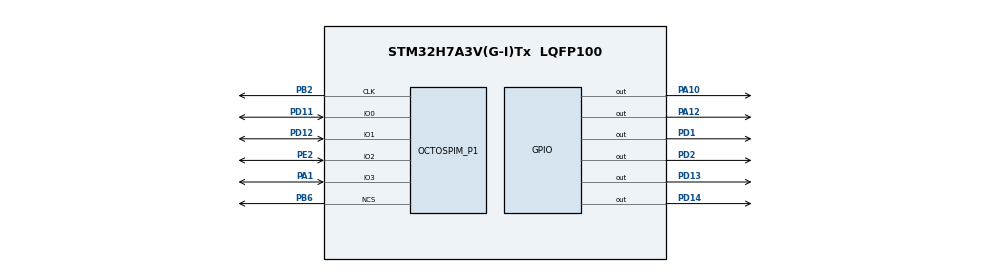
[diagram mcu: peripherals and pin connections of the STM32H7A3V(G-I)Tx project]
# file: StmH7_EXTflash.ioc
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CORTEX_M7.default_mode_Activation=1
Mcu.Family=STM32H7
Mcu.Name=STM32H7A3V(G-I)Tx
Mcu.Package=LQFP100
NVIC.PriorityGroup=NVIC_PRIORITYGROUP_4
OCTOSPI1.ClockPrescaler=2
OCTOSPI1.DeviceSize=20
OCTOSPI1.FifoThreshold=1
OCTOSPI1.SampleShifting=HAL_OSPI_SAMPLE_SHIFTING_NONE
PA1.Mode=OCTOSPI1_IOL_Port1L
PA1.Signal=OCTOSPIM_P1_IO3
PA10.Signal=GPIO_Output
PA12.Signal=GPIO_Output
PB2.Mode=O1_P1_CLK
PB2.Signal=OCTOSPIM_P1_CLK
PB6.Mode=OCTOSPI1_Port1_NCS
PB6.Signal=OCTOSPIM_P1_NCS
PD1.Signal=GPIO_Output
PD11.Mode=OCTOSPI1_IOL_Port1L
PD11.Signal=OCTOSPIM_P1_IO0
PD12.Mode=OCTOSPI1_IOL_Port1L
PD12.Signal=OCTOSPIM_P1_IO1
PD13.Signal=GPIO_Output
PD14.Signal=GPIO_Output
PD2.Signal=GPIO_Output
PE2.Mode=OCTOSPI1_IOL_Port1L
PE2.Signal=OCTOSPIM_P1_IO2
ProjectManager.HeapSize=0x200
ProjectManager.StackSize=0x400
ProjectManager.TargetToolchain=STM32CubeIDE
RCC.ADCFreq_Value=129000000
RCC.APB1Freq_Value=128000000
RCC.APB2Freq_Value=128000000
RCC.APB3Freq_Value=128000000
RCC.APB4Freq_Value=128000000
RCC.CortexFreq_Value=128000000
RCC.DIVM1=4
RCC.DIVN1=16
RCC.HCLKFreq_Value=128000000
RCC.PLL2FRACN=0
RCC.PLL3FRACN=0
RCC.PLLFRACN=0
RCC.SYSCLKFreq_VALUE=128000000
RCC.SYSCLKSource=RCC_SYSCLKSOURCE_PLLCLK
RCC.USBFreq_Value=128000000
VP_MEMORYMAP_VS_MEMORYMAP.Mode=CurAppReg
VP_OCTOSPI1_VS_quad.Mode=quad_mode
board=custom

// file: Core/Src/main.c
/* USER CODE BEGIN Header */
/**
  ******************************************************************************
  * @file           : main.c
  * @brief          : Main program body
  ******************************************************************************
  * @attention
  *
  * Copyright (c) 2026 STMicroelectronics.
  * All rights reserved.
  *
  * This software is licensed under terms that can be found in the LICENSE file
  * in the root directory of this software component.
  * If no LICENSE file comes with this software, it is provided AS-IS.
  *
  ******************************************************************************
  */
/* USER CODE END Header */
#include "main.h"
#include "octospi.h"
#include "gpio.h"

/* USER CODE BEGIN Includes */
#include <string.h>
#include <Loader_Src.h>
/* USER CODE END Includes */

/* USER CODE BEGIN PV */
//const uint8_t __attribute__((section(".extFlash"))) writebuf[] = "Hello world from QSPI";
//const uint8_t __attribute__((section(".extFlash"))) Readbuf[100] = {0};
//
//const uint8_t __attribute__((section(".extFlash"))) buf [] = "hello world from mappped qspi function";
/* USER CODE END PV */

void SystemClock_Config(void);
static void MPU_Config(void);

int main(void)
{

  /* MPU Configuration--------------------------------------------------------*/
  //MPU_Config();

  /* MCU Configuration--------------------------------------------------------*/

  /* Reset of all peripherals, Initializes the Flash interface and the Systick. */
  HAL_Init();

  /* Configure the system clock */
  SystemClock_Config();

  /* Initialize all configured peripherals */
  MX_GPIO_Init();
  MX_OCTOSPI1_Init();

  //Init();
  /* USER CODE BEGIN 2 */
 // if (CSP_QUADSPI_Init() != HAL_OK) Error_Handler();

   //if(CSP_QSPI_Erase_Chip() != HAL_OK ) Error_Handler();

  //if (CSP_QSPI_ReadMemory(Readbuf, 0, 100) != HAL_OK) Error_Handler();

  //if (CSP_QSPI_WriteMemory(writebuf, 0, sizeof(writebuf)) != HAL_OK) Error_Handler();

  //if(CSP_QSPI_EnableMemoryMappedMode() != HAL_OK) Error_Handler();

  //SCB_EnableDCache();

  //if (CSP_QSPI_ReadMemory(Readbuf, 0, 100) != HAL_OK) Error_Handler();
 // memcpy(Readbuf, (void*)0x90000000, sizeof(writebuf));
  /* USER CODE END 2 */

  /* Infinite loop */
  /* USER CODE BEGIN WHILE */
  while (1)
  {
//	  HAL_GPIO_TogglePin(GPIOD, GPIO_PIN_2);
//	  HAL_GPIO_TogglePin(GPIOD, GPIO_PIN_1);
//	  HAL_GPIO_TogglePin(GPIOD, GPIO_PIN_13);
//	  HAL_GPIO_TogglePin(GPIOA, GPIO_PIN_10);
//	  HAL_GPIO_TogglePin(GPIOA, GPIO_PIN_12);
//
//
//
//	  HAL_Delay(1000);
    /* USER CODE END WHILE */

  }
}

void SystemClock_Config(void)
{
  RCC_OscInitTypeDef RCC_OscInitStruct = {0};
  RCC_ClkInitTypeDef RCC_ClkInitStruct = {0};

  /*AXI clock gating */
  RCC->CKGAENR = 0xE003FFFF;

  /** Supply configuration update enable
  */
  HAL_PWREx_ConfigSupply(PWR_LDO_SUPPLY);

  /** Configure the main internal regulator output voltage
  */
  __HAL_PWR_VOLTAGESCALING_CONFIG(PWR_REGULATOR_VOLTAGE_SCALE2);

  while(!__HAL_PWR_GET_FLAG(PWR_FLAG_VOSRDY)) {}

  /** Initializes the RCC Oscillators according to the specified parameters
  * in the RCC_OscInitTypeDef structure.
  */
  RCC_OscInitStruct.OscillatorType = RCC_OSCILLATORTYPE_HSI;
  RCC_OscInitStruct.HSIState = RCC_HSI_DIV1;
  RCC_OscInitStruct.HSICalibrationValue = 64;
  RCC_OscInitStruct.PLL.PLLState = RCC_PLL_ON;
  RCC_OscInitStruct.PLL.PLLSource = RCC_PLLSOURCE_HSI;
  RCC_OscInitStruct.PLL.PLLM = 4;
  RCC_OscInitStruct.PLL.PLLN = 16;
  RCC_OscInitStruct.PLL.PLLP = 2;
  RCC_OscInitStruct.PLL.PLLQ = 2;
  RCC_OscInitStruct.PLL.PLLR = 2;
  RCC_OscInitStruct.PLL.PLLRGE = RCC_PLL1VCIRANGE_3;
  RCC_OscInitStruct.PLL.PLLVCOSEL = RCC_PLL1VCOWIDE;
  RCC_OscInitStruct.PLL.PLLFRACN = 0;
  if (HAL_RCC_OscConfig(&RCC_OscInitStruct) != HAL_OK)
  {
    Error_Handler();
  }

  /** Initializes the CPU, AHB and APB buses clocks
  */
  RCC_ClkInitStruct.ClockType = RCC_CLOCKTYPE_HCLK|RCC_CLOCKTYPE_SYSCLK
                              |RCC_CLOCKTYPE_PCLK1|RCC_CLOCKTYPE_PCLK2
                              |RCC_CLOCKTYPE_D3PCLK1|RCC_CLOCKTYPE_D1PCLK1;
  RCC_ClkInitStruct.SYSCLKSource = RCC_SYSCLKSOURCE_PLLCLK;
  RCC_ClkInitStruct.SYSCLKDivider = RCC_SYSCLK_DIV1;
  RCC_ClkInitStruct.AHBCLKDivider = RCC_HCLK_DIV1;
  RCC_ClkInitStruct.APB3CLKDivider = RCC_APB3_DIV1;
  RCC_ClkInitStruct.APB1CLKDivider = RCC_APB1_DIV1;
  RCC_ClkInitStruct.APB2CLKDivider = RCC_APB2_DIV1;
  RCC_ClkInitStruct.APB4CLKDivider = RCC_APB4_DIV1;

  if (HAL_RCC_ClockConfig(&RCC_ClkInitStruct, FLASH_LATENCY_3) != HAL_OK)
  {
    Error_Handler();
  }
}

 /* MPU Configuration */

void MPU_Config(void)
{
  MPU_Region_InitTypeDef MPU_InitStruct = {0};

  /* Disables the MPU */
  HAL_MPU_Disable();

  /** Initializes and configures the Region and the memory to be protected
  */
  MPU_InitStruct.Enable = MPU_REGION_ENABLE;
  MPU_InitStruct.Number = MPU_REGION_NUMBER0;
  MPU_InitStruct.BaseAddress = 0x0;
  MPU_InitStruct.Size = MPU_REGION_SIZE_4GB;
  MPU_InitStruct.SubRegionDisable = 0x87;
  MPU_InitStruct.TypeExtField = MPU_TEX_LEVEL0;
  MPU_InitStruct.AccessPermission = MPU_REGION_NO_ACCESS;
  MPU_InitStruct.DisableExec = MPU_INSTRUCTION_ACCESS_DISABLE;
  MPU_InitStruct.IsShareable = MPU_ACCESS_SHAREABLE;
  MPU_InitStruct.IsCacheable = MPU_ACCESS_NOT_CACHEABLE;
  MPU_InitStruct.IsBufferable = MPU_ACCESS_NOT_BUFFERABLE;

  HAL_MPU_ConfigRegion(&MPU_InitStruct);
  /* Enables the MPU */
  HAL_MPU_Enable(MPU_PRIVILEGED_DEFAULT);

}

void Error_Handler(void)
{
  /* USER CODE BEGIN Error_Handler_Debug */
  /* User can add his own implementation to report the HAL error return state */
  __disable_irq();
  while (1)
  {
	  HAL_GPIO_TogglePin(GPIOD, GPIO_PIN_14);
  }

  /* USER CODE END Error_Handler_Debug */
}
